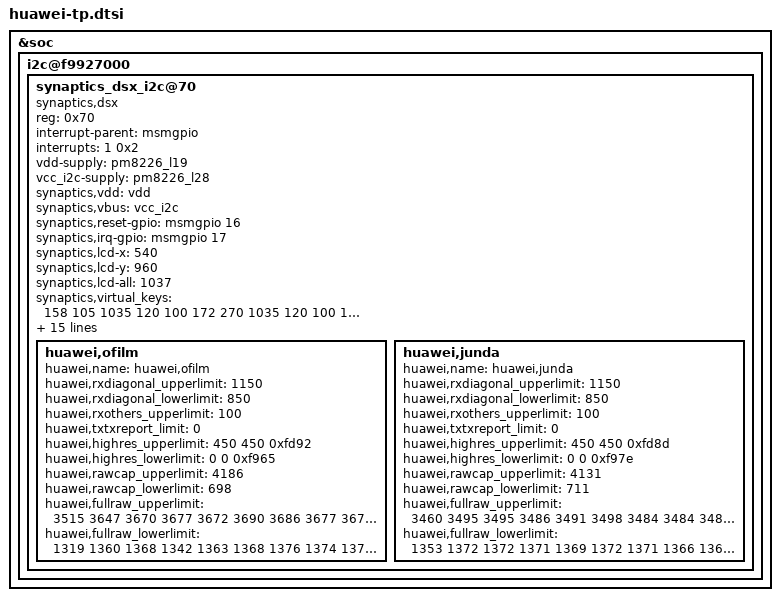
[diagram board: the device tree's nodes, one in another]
/*Add synaptics new driver "Synaptics DSX I2C V2.0"*/
/*Modified the virtual key width and x coordinate*/
&soc{
	i2c@f9927000 {
		status = "ok";
		synaptics_dsx_i2c@70 {
			compatible = "synaptics,dsx";
			reg = <0x70>;
			interrupt-parent = <&msmgpio>;
			interrupts = <1 0x2>;
			vdd-supply = <&pm8226_l19>;
			vcc_i2c-supply = <&pm8226_l28>;
			synaptics,vdd = "vdd";
			synaptics,vbus = "vcc_i2c";
			synaptics,reset-gpio = <&msmgpio 16 0x00>;
			synaptics,irq-gpio = <&msmgpio 17 0x00>;

			synaptics,lcd-x = <540>;
			synaptics,lcd-y = <960>;
			synaptics,lcd-all = <1037>;
			synaptics,virtual_keys = /* KeyCode CenterX CenterY Width Height */
				/* KEY_BACK */
				<158 105 1035 120 100
				/* KEY_HOMEPAGE instead of KEY_HOME(102) */
				172 270 1035 120 100
				/* KEY_MENU */
				139 435 1035 120 100>;

			/* SYNAPTICS_WAKE_UP_GESTURE_FLAG:'1'->enabled,'0'->disabled */
			/*IC flash is not enough for holster,so del one gesture*/
			synaptics,gesture_enabled = <0>;
			/* Gestures that supported:                           */
			/* bit0  Double tap                                        */
			/* bit1  Single finger slide from left to right     */
			/* bit2  Single finger slide from right to left     */
			/* bit3  Single finger slide from top to bottom  */
			/* bit4  Single finger slide from bottom to top  */
			/* bit5  Double finger slide from top to bottom--disable for holster*/
			/* bit6  Single finger slide circle                     */
			/* bit7  Single finger write letter c                  */
			/* bit8  Single finger write letter e                  */
			/* bit9  Single finger write letter m                 */
			/* bit10 Single finger write letter w                 */
			/* bit11 Palm off screen                                */
			synaptics,easy_wakeup_supported_gestures = <0xFDF>;

			/*Defination of report key value  for different gestures*/
			synaptics,easy_wakeup_gesture_keys = 
			<	59 /*0.Double tap:KEY_F1*/
				60 /*1.Single finger slide from left to right*/
				61 /*2.Single finger slide from right to left:KEY_F3*/
				62 /*3.Single finger slide from top to bottom*/
				63 /*4.Single finger slide from bottom to top:KEY_F5*/
				64 /*5.Double finger slide from top to bottom*/
				65 /*6.Single finger slide circle:KEY_F7*/
				66 /*7.Single finger write letter c*/
				67 /*8.Single finger write letter e:KEY_F9*/
				68 /*9.Single finger write letter m*/
				87 /*10.Single finger write letter w:KEY_F11*/
				88 /*11.Palm off screen*/
			>;

			/* Double-tap-zone defined by huawei */
			/* Shielded area is:1cm left,1cm right,3cm up,2cm down */
			huawei,dtz_x0 = <87>;
			huawei,dtz_y0 = <262>;
			huawei,dtz_x1 = <453>;
			huawei,dtz_y1 = <785>;

			/* SYNAPTICS_GLOVE_FUNCTION_FLAG:'1'->enabled,'0'->disabled*/
			synaptics,glove_enabled = <0>;

			synaptics,reset-on-status = <0>;
			synaptics,power-delay-ms = <160>;
			synaptics,reset-delay-ms = <100>;
			synaptics,reset-active-ms = <90>;
			/*Use to combine fw name*/
			synaptics,product_name = "g620L";

			/*capacitance self-adapt*/
			huawei,ofilm {
				huawei,name = "huawei,ofilm";
				huawei,rxdiagonal_upperlimit = <1150>;
				huawei,rxdiagonal_lowerlimit = <850>;
				huawei,rxothers_upperlimit = <100>;
				huawei,txtxreport_limit = <0>;
				huawei,highres_upperlimit = <450 450 0xfd92>;/*0xfd92==-622*/
				huawei,highres_lowerlimit = <0 0 0xf965>;/*0xf965==-1691*/
				huawei,rawcap_upperlimit = <4186>;
				huawei,rawcap_lowerlimit = <698>;

				huawei,fullraw_upperlimit =
					<3515 3647 3670 3677 3672 3690 3686 3677 3677 3675 3662 3659 3501 3501 3481 3495 3487 3479 3469 3479 3476 3474 3473 1912
					3537 3595 3595 3605 3602 3612 3613 3605 3605 3609 3592 3592 3570 3570 3557 3563 3556 3549 3535 3550 3547 3547 3557 3546
					3526 3589 3596 3607 3605 3607 3612 3603 3610 3607 3592 3593 3577 3578 3567 3575 3568 3557 3553 3563 3560 3558 3564 3914
					3519 3584 3589 3602 3595 3603 3606 3602 3605 3606 3593 3592 3588 3591 3582 3586 3578 3565 3560 3570 3565 3564 3575 3574
					3519 3588 3593 3602 3598 3603 3600 3598 3598 3609 3592 3588 3595 3593 3588 3591 3589 3572 3568 3579 3578 3577 3591 3550
					3519 3586 3593 3600 3595 3593 3593 3592 3592 3599 3584 3584 3595 3603 3589 3603 3596 3584 3582 3591 3589 3588 3600 3613
					3519 3575 3582 3591 3581 3586 3581 3564 3575 3589 3572 3575 3598 3600 3591 3593 3591 3582 3581 3589 3589 3588 3609 4179
					3511 3572 3572 3584 3572 3586 3568 3560 3567 3577 3560 3564 3605 3612 3599 3607 3596 3586 3584 3595 3595 3599 3614 3649
					3504 3563 3550 3571 3571 3571 3556 3563 3561 3571 3561 3567 3613 3614 3607 3609 3607 3598 3592 3600 3606 3607 3623 3588
					3500 3560 3551 3571 3568 3570 3563 3563 3563 3571 3563 3561 3619 3626 3613 3624 3610 3600 3599 3612 3610 3613 3620 3659
					3500 3557 3561 3568 3565 3567 3567 3561 3560 3571 3558 3558 3620 3626 3616 3628 3621 3602 3593 3609 3610 3612 3621 4186
					3497 3549 3551 3563 3558 3560 3557 3556 3556 3570 3557 3556 3637 3645 3623 3640 3626 3614 3606 3623 3619 3623 3631 3642
					3378 3427 3434 3445 3441 3448 3441 3448 3448 3455 3453 3456 4085 3985 3906 3851 3810 3771 3752 3754 3739 3721 3722 2199>;

				huawei,fullraw_lowerlimit =
					<1319 1360 1368 1342 1363 1368 1376 1374 1378 1373 1370 1376 1320 1319 1320 1315 1313 1313 1314 1311 1310 1314 1311 697
					1332 1343 1343 1278 1335 1339 1350 1352 1357 1354 1350 1356 1348 1350 1350 1348 1346 1349 1346 1344 1344 1348 1348 1340
					1331 1344 1343 1315 1333 1337 1346 1352 1352 1352 1352 1353 1352 1349 1352 1350 1349 1349 1347 1349 1344 1350 1348 1427
					1328 1341 1340 1335 1328 1334 1334 1340 1352 1349 1350 1348 1348 1347 1349 1344 1344 1346 1345 1346 1344 1351 1352 1341
					1328 1343 1338 1328 1325 1317 1331 1339 1346 1338 1337 1340 1349 1342 1348 1345 1343 1345 1346 1341 1347 1349 1350 1332
					1327 1342 1337 1322 1321 1311 1308 1335 1338 1334 1328 1329 1344 1345 1344 1343 1345 1343 1346 1346 1345 1350 1352 1344
					1326 1342 1331 1319 1320 1317 1303 1325 1331 1329 1325 1323 1342 1342 1344 1343 1346 1348 1347 1347 1346 1352 1353 1467
					1323 1340 1317 1313 1314 1313 1317 1312 1325 1329 1320 1319 1341 1343 1344 1346 1346 1350 1347 1348 1350 1354 1356 1352
					1318 1325 1308 1310 1311 1313 1314 1315 1322 1325 1314 1312 1335 1345 1342 1346 1349 1350 1350 1349 1350 1354 1359 1343
					1319 1320 1298 1301 1300 1306 1301 1305 1309 1317 1319 1317 1335 1343 1335 1346 1348 1356 1352 1355 1353 1358 1361 1364
					1314 1319 1298 1300 1299 1296 1291 1291 1298 1304 1311 1314 1335 1336 1337 1344 1347 1357 1359 1358 1358 1360 1365 1477
					1314 1320 1298 1301 1296 1289 1284 1280 1287 1293 1305 1305 1338 1343 1339 1350 1349 1361 1362 1365 1364 1369 1371 1356
					1289 1295 1273 1275 1271 1262 1259 1254 1255 1263 1272 1277 1449 1437 1425 1414 1407 1410 1401 1398 1398 1391 1385 786>;
			};
			huawei,junda {
				huawei,name = "huawei,junda";
				huawei,rxdiagonal_upperlimit = <1150>;
				huawei,rxdiagonal_lowerlimit = <850>;
				huawei,rxothers_upperlimit = <100>;
				huawei,txtxreport_limit = <0>;
				huawei,highres_upperlimit = <450 450 0xfd8d>;/*0xfd8d==-627*/
				huawei,highres_lowerlimit = <0 0 0xf97e>;/*0xf97e==-1666*/
				huawei,rawcap_upperlimit = <4131>;
				huawei,rawcap_lowerlimit = <711>;

				huawei,fullraw_upperlimit =
					<3460 3495 3495 3486 3491 3498 3484 3484 3480 3481 3466 3448 4135 3893 3866 3840 3806 3792 3784 3771 3767 3770 3750 2381
					3481 3515 3512 3507 3502 3502 3505 3497 3480 3479 3472 3452 3553 3526 3530 3533 3514 3518 3515 3512 3522 3522 3518 3467
					3483 3518 3516 3512 3507 3508 3509 3502 3484 3486 3474 3465 3525 3514 3511 3515 3500 3500 3497 3493 3508 3504 3507 3571
					3486 3515 3512 3514 3502 3508 3509 3501 3488 3486 3473 3466 3500 3497 3498 3501 3488 3483 3483 3484 3500 3495 3497 3441
					3493 3516 3518 3522 3500 3504 3502 3497 3487 3483 3474 3460 3486 3477 3484 3484 3470 3469 3466 3472 3487 3484 3487 3410
					3500 3528 3530 3526 3500 3505 3504 3491 3483 3477 3469 3462 3467 3463 3463 3467 3453 3448 3451 3458 3476 3466 3467 3414
					3519 3536 3539 3535 3505 3505 3501 3490 3491 3483 3477 3460 3456 3453 3455 3458 3444 3442 3445 3448 3460 3452 3449 3554
					3525 3540 3546 3540 3515 3514 3507 3502 3500 3500 3490 3476 3449 3452 3453 3449 3438 3434 3441 3441 3448 3460 3441 3397
					3532 3550 3549 3542 3521 3519 3519 3518 3512 3507 3493 3484 3438 3444 3445 3439 3434 3430 3434 3438 3442 3449 3434 3375
					3543 3553 3556 3547 3529 3532 3529 3514 3511 3512 3500 3493 3435 3438 3438 3435 3428 3424 3430 3432 3438 3441 3424 3393
					3554 3564 3561 3558 3539 3535 3535 3519 3518 3516 3512 3504 3437 3434 3437 3439 3427 3427 3431 3425 3430 3438 3420 3514
					3557 3578 3575 3567 3542 3544 3544 3535 3532 3536 3523 3522 3431 3428 3435 3434 3423 3416 3427 3418 3427 3435 3418 3358
					3802 3805 3817 3826 3834 3833 3791 3773 3761 3760 3735 3799 3441 3435 3437 3442 3430 3421 3417 3416 3416 3421 3396 1913>;

				huawei,fullraw_lowerlimit =
					<1353 1372 1372 1371 1369 1372 1371 1366 1362 1265 1254 1283 1572 1497 1485 1460 1450 1442 1435 1424 1415 1411 1400 823
					1359 1377 1373 1372 1374 1379 1374 1368 1363 1275 1265 1289 1379 1365 1361 1312 1304 1343 1341 1340 1337 1332 1323 1307
					1355 1364 1364 1368 1370 1374 1368 1361 1350 1277 1266 1289 1367 1355 1350 1298 1292 1332 1331 1332 1334 1334 1324 1354
					1356 1364 1365 1367 1369 1367 1360 1352 1343 1280 1269 1288 1353 1343 1338 1290 1283 1325 1322 1325 1328 1330 1326 1314
					1356 1368 1368 1366 1356 1355 1347 1346 1336 1282 1269 1288 1345 1336 1332 1284 1276 1316 1319 1319 1322 1328 1327 1311
					1356 1365 1362 1358 1345 1340 1341 1340 1336 1283 1267 1287 1338 1334 1327 1274 1268 1311 1290 1317 1319 1323 1324 1310
					1357 1362 1354 1347 1344 1336 1340 1339 1337 1289 1277 1287 1335 1333 1328 1267 1262 1312 1281 1317 1319 1321 1318 1357
					1356 1355 1350 1346 1341 1342 1343 1343 1341 1296 1286 1294 1331 1329 1310 1262 1255 1303 1275 1304 1310 1313 1306 1296
					1355 1356 1352 1348 1344 1346 1345 1345 1349 1303 1294 1299 1323 1324 1289 1257 1250 1304 1273 1297 1298 1301 1297 1285
					1357 1356 1354 1358 1355 1353 1353 1351 1356 1311 1300 1308 1317 1318 1286 1253 1248 1304 1269 1293 1286 1284 1289 1287
					1359 1359 1359 1358 1359 1359 1360 1359 1359 1316 1304 1318 1314 1316 1285 1252 1248 1304 1267 1296 1284 1279 1284 1328
					1359 1355 1356 1356 1353 1356 1358 1361 1362 1325 1313 1328 1316 1318 1284 1250 1244 1308 1264 1301 1292 1289 1289 1277
					1415 1414 1416 1415 1415 1416 1413 1416 1415 1409 1415 1420 1323 1326 1286 1253 1248 1318 1260 1314 1307 1304 1298 713>;
			};
		};
	};
};

